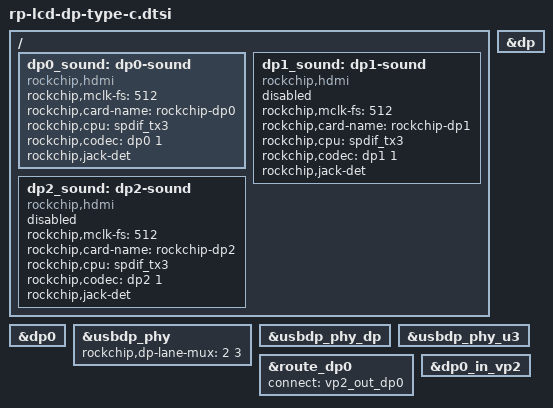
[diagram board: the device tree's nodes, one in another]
/{
    dp0_sound: dp0-sound {
        status = "disabled";
        compatible = "rockchip,hdmi";
        rockchip,mclk-fs = <512>;
        rockchip,card-name = "rockchip-dp0";
        rockchip,cpu = <&spdif_tx3>;
        rockchip,codec = <&dp0 1>;
        rockchip,jack-det;
    };

    dp1_sound: dp1-sound {
        status = "disabled";
        compatible = "rockchip,hdmi";
        rockchip,mclk-fs = <512>;
        rockchip,card-name = "rockchip-dp1";
        rockchip,cpu = <&spdif_tx3>;
        rockchip,codec = <&dp1 1>;
        rockchip,jack-det;
    };

    dp2_sound: dp2-sound {
        status = "disabled";
        compatible = "rockchip,hdmi";
        rockchip,mclk-fs = <512>;
        rockchip,card-name = "rockchip-dp2";
        rockchip,cpu = <&spdif_tx3>;
        rockchip,codec = <&dp2 1>;
        rockchip,jack-det;
    };    
};

&dp {
//    pinctrl-0 = <&dpm1_pins>;
//    pinctrl-names = "default";
    status = "okay";
};

&dp0 {
    status = "okay";
};

&usbdp_phy {
    rockchip,dp-lane-mux = <2 3>;
    status = "okay";
};

&usbdp_phy_dp {
    status = "okay";
};

&usbdp_phy_u3 {
    status = "okay";
};

&dp0_sound {
    status = "okay";
};

&route_dp0{
    status = "okay";
    connect = <&vp2_out_dp0>;
};

&dp0_in_vp2 {
    status = "okay";
};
